VERSION "HNPBNYYYYYYYYYYYYYYYYYYYYYYYYYYYNNNNNNNNNN/4/%%%/4/'%**4NNN///"
NS_ :

BS_:

BU_: BDC546 imc_BUSFX_2_133754 Sender__XXX WC Xsens_Sensor

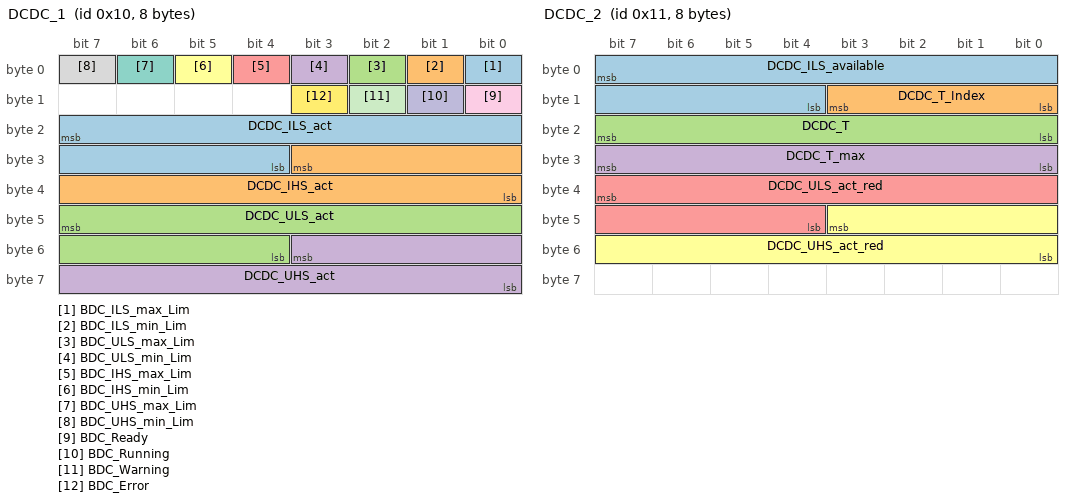
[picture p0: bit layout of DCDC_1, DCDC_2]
BO_ 16 DCDC_1: 8 BDC546
 SG_ BDC_ILS_max_Lim : 0|1@1+ (1,0) [0|1] ""  imc_BUSFX_2_133754
 SG_ BDC_ILS_min_Lim : 1|1@1+ (1,0) [0|1] ""  imc_BUSFX_2_133754
 SG_ BDC_ULS_max_Lim : 2|1@1+ (1,0) [0|1] ""  imc_BUSFX_2_133754
 SG_ BDC_ULS_min_Lim : 3|1@1+ (1,0) [0|1] ""  imc_BUSFX_2_133754
 SG_ BDC_IHS_max_Lim : 4|1@1+ (1,0) [0|1] ""  imc_BUSFX_2_133754
 SG_ BDC_IHS_min_Lim : 5|1@1+ (1,0) [0|1] ""  imc_BUSFX_2_133754
 SG_ BDC_UHS_max_Lim : 6|1@1+ (1,0) [0|1] ""  imc_BUSFX_2_133754
 SG_ BDC_UHS_min_Lim : 7|1@1+ (1,0) [0|1] ""  imc_BUSFX_2_133754
 SG_ BDC_Ready : 8|1@1+ (1,0) [0|1] ""  imc_BUSFX_2_133754
 SG_ BDC_Running : 9|1@1+ (1,0) [0|1] ""  imc_BUSFX_2_133754
 SG_ BDC_Warning : 10|1@1+ (1,0) [0|1] ""  imc_BUSFX_2_133754
 SG_ BDC_Error : 11|1@1+ (1,0) [0|1] ""  imc_BUSFX_2_133754
 SG_ DCDC_ILS_act : 23|12@0+ (2.500000000E-1,-5.120000000E+2) [-5.120000000E+2|5.117500000E+2] "A"  imc_BUSFX_2_133754
 SG_ DCDC_IHS_act : 27|12@0+ (2.500000000E-1,-5.120000000E+2) [-5.120000000E+2|5.117500000E+2] "A"  imc_BUSFX_2_133754
 SG_ DCDC_ULS_act : 47|12@0+ (2.500000000E-1,0.000000000E+0) [0.000000000E+0|1.023750000E+3] "V"  imc_BUSFX_2_133754
 SG_ DCDC_UHS_act : 51|12@0+ (2.500000000E-1,0.000000000E+0) [0.000000000E+0|1.023750000E+3] "V"  imc_BUSFX_2_133754

BO_ 17 DCDC_2: 8 BDC546
 SG_ DCDC_ILS_available : 7|12@0+ (2.500000000E-1,0.000000000E+0) [0.000000000E+0|1.023750000E+3] "A"  imc_BUSFX_2_133754
 SG_ DCDC_T_Index : 11|4@0+ (1.000000000E+0,0.000000000E+0) [0.000000000E+0|1.500000000E+1] ""  imc_BUSFX_2_133754
 SG_ DCDC_T : 23|8@0+ (1.000000000E+0,-4.000000000E+1) [-4.000000000E+1|2.150000000E+2] "C"  imc_BUSFX_2_133754
 SG_ DCDC_T_max : 31|8@0+ (1.000000000E+0,-4.000000000E+1) [-4.000000000E+1|2.150000000E+2] "C"  imc_BUSFX_2_133754
 SG_ DCDC_ULS_act_red : 39|12@0+ (2.500000000E-1,0.000000000E+0) [0.000000000E+0|1.023750000E+3] "V"  imc_BUSFX_2_133754
 SG_ DCDC_UHS_act_red : 43|12@0+ (2.500000000E-1,0.000000000E+0) [0.000000000E+0|1.023750000E+3] "V"  imc_BUSFX_2_133754

BO_ 18 DCDC_3: 8 BDC546
 SG_ BDC_Err_RedNegLS : 0|1@1+ (1,0) [0|1] ""  imc_BUSFX_2_133754
 SG_ BDC_Err_RedPosLS : 1|1@1+ (1,0) [0|1] ""  imc_BUSFX_2_133754
 SG_ BDC_Err_PyroMC : 2|1@1+ (1,0) [0|1] ""  imc_BUSFX_2_133754
 SG_ BDC_Err_TempSens : 8|1@1+ (1,0) [0|1] ""  imc_BUSFX_2_133754
 SG_ BDC_Err_Interlock : 9|1@1+ (1,0) [0|1] ""  imc_BUSFX_2_133754
 SG_ BDC_Err_ISensLS : 10|1@1+ (1,0) [0|1] ""  imc_BUSFX_2_133754
 SG_ BDC_Err_ISensHS : 11|1@1+ (1,0) [0|1] ""  imc_BUSFX_2_133754
 SG_ BDC_Err_BDCMode : 12|1@1+ (1,0) [0|1] ""  imc_BUSFX_2_133754
 SG_ BDC_Err_IHS2ILS : 13|1@1+ (1,0) [0|1] ""  imc_BUSFX_2_133754
 SG_ BDC_Err_RedNegHS : 14|1@1+ (1,0) [0|1] ""  imc_BUSFX_2_133754
 SG_ BDC_Err_RedPosHS : 15|1@1+ (1,0) [0|1] ""  imc_BUSFX_2_133754
 SG_ BDC_Err_Timeout_Recv3 : 19|1@1+ (1,0) [0|1] ""  imc_BUSFX_2_133754
 SG_ BDC_Err_Timeout_Recv2 : 20|1@1+ (1,0) [0|1] ""  imc_BUSFX_2_133754
 SG_ BDC_Err_Timeout_Recv1 : 21|1@1+ (1,0) [0|1] ""  imc_BUSFX_2_133754
 SG_ BDC_Err_CANValue : 22|1@1+ (1,0) [0|1] ""  imc_BUSFX_2_133754
 SG_ BDC_Err_IntSupply : 23|1@1+ (1,0) [0|1] ""  imc_BUSFX_2_133754
 SG_ BDC_Err_FPGA : 3|1@1+ (1,0) [0|1] ""  imc_BUSFX_2_133754
 SG_ BDC_Err_NVSRam : 4|1@1+ (1,0) [0|1] ""  imc_BUSFX_2_133754
 SG_ BDC_Err_Flash : 5|1@1+ (1,0) [0|1] ""  imc_BUSFX_2_133754
 SG_ BDC_Err_EEProm : 6|1@1+ (1,0) [0|1] ""  imc_BUSFX_2_133754
 SG_ BDC_Err_HW_FPGA_Ver : 7|1@1+ (1,0) [0|1] ""  imc_BUSFX_2_133754
 SG_ BDC_Err_CANTx : 16|1@1+ (1,0) [0|1] ""  imc_BUSFX_2_133754
 SG_ BDC_Err_CANRx : 17|1@1+ (1,0) [0|1] ""  imc_BUSFX_2_133754
 SG_ BDC_Err_CANOff : 18|1@1+ (1,0) [0|1] ""  imc_BUSFX_2_133754
 SG_ BDC_Err_OvltSky : 29|1@1+ (1,0) [0|1] ""  imc_BUSFX_2_133754
 SG_ BDC_Err_OvltLS : 30|1@1+ (1,0) [0|1] ""  imc_BUSFX_2_133754
 SG_ BDC_Err_OvltHS : 31|1@1+ (1,0) [0|1] ""  imc_BUSFX_2_133754
 SG_ BDC_War_TempIndD : 32|1@1+ (1,0) [0|1] ""  imc_BUSFX_2_133754
 SG_ BDC_War_TempIndC : 33|1@1+ (1,0) [0|1] ""  imc_BUSFX_2_133754
 SG_ BDC_War_TempIndB : 34|1@1+ (1,0) [0|1] ""  imc_BUSFX_2_133754
 SG_ BDC_War_TempIndA : 35|1@1+ (1,0) [0|1] ""  imc_BUSFX_2_133754
 SG_ BDC_War_Reset : 36|1@1+ (1,0) [0|1] ""  imc_BUSFX_2_133754
 SG_ BDC_War_IMax : 37|1@1+ (1,0) [0|1] ""  imc_BUSFX_2_133754
 SG_ BDC_War_Watchdog : 38|1@1+ (1,0) [0|1] ""  imc_BUSFX_2_133754
 SG_ BDC_War_TempL2x : 45|1@1+ (1,0) [0|1] ""  imc_BUSFX_2_133754
 SG_ BDC_War_TempL1y : 46|1@1+ (1,0) [0|1] ""  imc_BUSFX_2_133754
 SG_ BDC_War_TempL1x : 47|1@1+ (1,0) [0|1] ""  imc_BUSFX_2_133754
 SG_ BDC_Err_FPGA_NVM : 28|1@1+ (1,0) [0|1] ""  imc_BUSFX_2_133754
 SG_ BDC_War_TempL4y : 40|1@1+ (1,0) [0|1] ""  imc_BUSFX_2_133754
 SG_ BDC_War_TempL4x : 41|1@1+ (1,0) [0|1] ""  imc_BUSFX_2_133754
 SG_ BDC_War_TempL3y : 42|1@1+ (1,0) [0|1] ""  imc_BUSFX_2_133754
 SG_ BDC_War_TempL3x : 43|1@1+ (1,0) [0|1] ""  imc_BUSFX_2_133754
 SG_ BDC_War_TempL2y : 44|1@1+ (1,0) [0|1] ""  imc_BUSFX_2_133754
 SG_ BDC_War_HSOvervoltage : 48|1@1+ (1,0) [0|1] ""  imc_BUSFX_2_133754
 SG_ BDC_War_NoIntSupply : 49|1@1+ (1,0) [0|1] ""  imc_BUSFX_2_133754
 SG_ BDC_War_NoHV_UHS : 50|1@1+ (1,0) [0|1] ""  imc_BUSFX_2_133754
 SG_ BDC_War_WrongFPGA : 51|1@1+ (1,0) [0|1] ""  imc_BUSFX_2_133754
 SG_ BDC_War_WrongHW : 52|1@1+ (1,0) [0|1] ""  imc_BUSFX_2_133754
 SG_ BDC_War_PyroVCneg : 53|1@1+ (1,0) [0|1] ""  imc_BUSFX_2_133754
 SG_ BDC_War_PyroVCpos : 54|1@1+ (1,0) [0|1] ""  imc_BUSFX_2_133754
 SG_ BDC_War_Discharge : 55|1@1+ (1,0) [0|1] ""  imc_BUSFX_2_133754
 SG_ BDC_War_CAN_Timeout : 62|1@1+ (1,0) [0|1] ""  imc_BUSFX_2_133754
 SG_ BDC_War_LSOvervoltage : 63|1@1+ (1,0) [0|1] ""  imc_BUSFX_2_133754

BO_ 19 DCDC_4: 8 BDC546
 SG_ BDC_FPGA_SsErr0 : 0|1@1+ (1,0) [0|1] ""  imc_BUSFX_2_133754
 SG_ BDC_FPGA_SsErr1 : 1|1@1+ (1,0) [0|1] ""  imc_BUSFX_2_133754
 SG_ BDC_FPGA_SsErr2 : 2|1@1+ (1,0) [0|1] ""  imc_BUSFX_2_133754
 SG_ BDC_FPGA_SsErr3 : 3|1@1+ (1,0) [0|1] ""  imc_BUSFX_2_133754
 SG_ BDC_FPGA_SsErr4 : 4|1@1+ (1,0) [0|1] ""  imc_BUSFX_2_133754
 SG_ BDC_FPGA_SsErr5 : 5|1@1+ (1,0) [0|1] ""  imc_BUSFX_2_133754
 SG_ BDC_FPGA_SsErr6 : 6|1@1+ (1,0) [0|1] ""  imc_BUSFX_2_133754
 SG_ BDC_FPGA_SsErr7 : 7|1@1+ (1,0) [0|1] ""  imc_BUSFX_2_133754
 SG_ BDC_FPGA_ILmaxErr0 : 8|1@1+ (1,0) [0|1] ""  imc_BUSFX_2_133754
 SG_ BDC_FPGA_ILmaxErr1 : 9|1@1+ (1,0) [0|1] ""  imc_BUSFX_2_133754
 SG_ BDC_FPGA_ILmaxErr2 : 10|1@1+ (1,0) [0|1] ""  imc_BUSFX_2_133754
 SG_ BDC_FPGA_ILmaxErr3 : 11|1@1+ (1,0) [0|1] ""  imc_BUSFX_2_133754
 SG_ BDC_FPGA_ILmaxErr4 : 12|1@1+ (1,0) [0|1] ""  imc_BUSFX_2_133754
 SG_ BDC_FPGA_ILmaxErr5 : 13|1@1+ (1,0) [0|1] ""  imc_BUSFX_2_133754
 SG_ BDC_FPGA_ILmaxErr6 : 14|1@1+ (1,0) [0|1] ""  imc_BUSFX_2_133754
 SG_ BDC_FPGA_ILmaxErr7 : 15|1@1+ (1,0) [0|1] ""  imc_BUSFX_2_133754
 SG_ BDC_FPGA_UBmaxErr : 16|1@1+ (1,0) [0|1] ""  imc_BUSFX_2_133754
 SG_ BDC_FPGA_UA1maxErr : 17|1@1+ (1,0) [0|1] ""  imc_BUSFX_2_133754
 SG_ BDC_FPGA_U15VmaxErr : 18|1@1+ (1,0) [0|1] ""  imc_BUSFX_2_133754
 SG_ BDC_FPGA_IBmaxErr : 23|1@1+ (1,0) [0|1] ""  imc_BUSFX_2_133754
 SG_ BDC_FPGA_GenRglPer : 24|1@1+ (1,0) [0|1] ""  imc_BUSFX_2_133754
 SG_ BDC_FPGA_IllegalAccess : 27|1@1+ (1,0) [0|1] ""  imc_BUSFX_2_133754
 SG_ BDC_FPGA_Hw_Err0 : 28|1@1+ (1,0) [0|1] ""  imc_BUSFX_2_133754
 SG_ BDC_FPGA_Hw_Err1 : 29|1@1+ (1,0) [0|1] ""  imc_BUSFX_2_133754
 SG_ DCDC_FPGA_IntStatUnused3 : 22|4@0- (1.000000000E+0,0.000000000E+0) [-8.000000000E+0|7.000000000E+0] ""  imc_BUSFX_2_133754
 SG_ DCDC_FPGA_IntStatUnused1 : 26|2@0- (1.000000000E+0,0.000000000E+0) [-2.000000000E+0|1.000000000E+0] ""  imc_BUSFX_2_133754
 SG_ DCDC_FPGA_IntStatUnused2 : 31|2@0- (1.000000000E+0,0.000000000E+0) [-2.000000000E+0|1.000000000E+0] ""  imc_BUSFX_2_133754
 SG_ DCDC_CAN_RXCNT : 39|8@0+ (1.000000000E+0,0.000000000E+0) [0.000000000E+0|2.550000000E+2] ""  imc_BUSFX_2_133754
 SG_ DCDC_CAN_TXCNT : 47|8@0+ (1.000000000E+0,0.000000000E+0) [0.000000000E+0|2.550000000E+2] ""  imc_BUSFX_2_133754
 SG_ DCDC_SG_IL_max : 55|16@0+ (3.125000000E-2,-1.024000000E+3) [-1.024000000E+3|1.023968750E+3] "A"  imc_BUSFX_2_133754

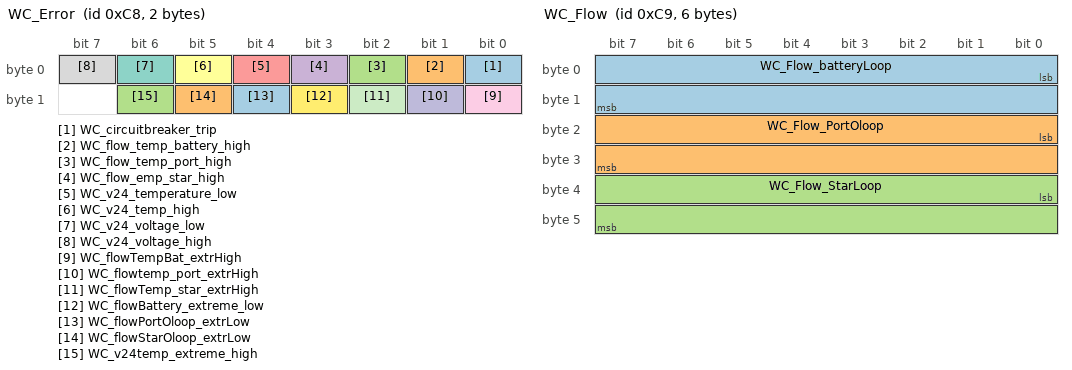
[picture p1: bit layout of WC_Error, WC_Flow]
BO_ 200 WC_Error: 2 Sender__XXX
 SG_ WC_circuitbreaker_trip : 0|1@1+ (1,0) [0|1] ""  imc_BUSFX_2_133754
 SG_ WC_flow_temp_battery_high : 1|1@1+ (1,0) [0|1] ""  imc_BUSFX_2_133754
 SG_ WC_flow_temp_port_high : 2|1@1+ (1,0) [0|1] ""  imc_BUSFX_2_133754
 SG_ WC_flow_emp_star_high : 3|1@1+ (1,0) [0|1] ""  imc_BUSFX_2_133754
 SG_ WC_v24_temperature_low : 4|1@1+ (1,0) [0|1] ""  imc_BUSFX_2_133754
 SG_ WC_v24_temp_high : 5|1@1+ (1,0) [0|1] ""  imc_BUSFX_2_133754
 SG_ WC_v24_voltage_low : 6|1@1+ (1,0) [0|1] ""  imc_BUSFX_2_133754
 SG_ WC_v24_voltage_high : 7|1@1+ (1,0) [0|1] ""  imc_BUSFX_2_133754
 SG_ WC_flowTempBat_extrHigh : 8|1@1+ (1,0) [0|1] ""  imc_BUSFX_2_133754
 SG_ WC_flowtemp_port_extrHigh : 9|1@1+ (1,0) [0|1] ""  imc_BUSFX_2_133754
 SG_ WC_flowTemp_star_extrHigh : 10|1@1+ (1,0) [0|1] ""  imc_BUSFX_2_133754
 SG_ WC_flowBattery_extreme_low : 11|1@1+ (1,0) [0|1] ""  imc_BUSFX_2_133754
 SG_ WC_flowPortOloop_extrLow : 12|1@1+ (1,0) [0|1] ""  imc_BUSFX_2_133754
 SG_ WC_flowStarOloop_extrLow : 13|1@1+ (1,0) [0|1] ""  imc_BUSFX_2_133754
 SG_ WC_v24temp_extreme_high : 14|1@1+ (1,0) [0|1] ""  imc_BUSFX_2_133754

BO_ 201 WC_Flow: 6 Sender__XXX
 SG_ WC_Flow_batteryLoop : 0|16@1+ (7.629510948E-4,0.000000000E+0) [0.000000000E+0|5.000000000E+1] "L/min"  imc_BUSFX_2_133754
 SG_ WC_Flow_PortOloop : 16|16@1+ (7.629510948E-4,0.000000000E+0) [0.000000000E+0|5.000000000E+1] "L/min"  imc_BUSFX_2_133754
 SG_ WC_Flow_StarLoop : 32|16@1+ (7.629510948E-4,0.000000000E+0) [0.000000000E+0|5.000000000E+1] "L/min"  imc_BUSFX_2_133754

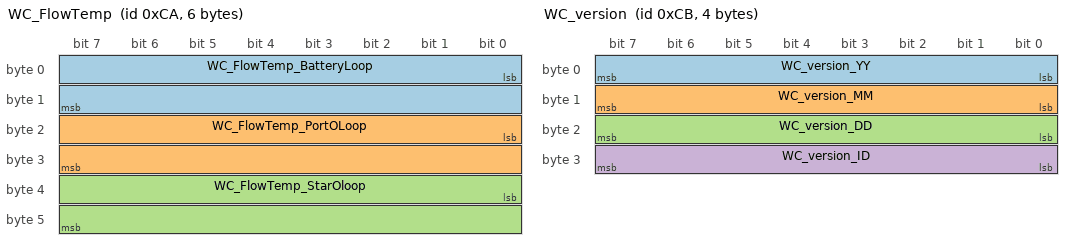
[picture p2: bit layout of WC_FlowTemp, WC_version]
BO_ 202 WC_FlowTemp: 6 Sender__XXX
 SG_ WC_FlowTemp_BatteryLoop : 0|16@1+ (2.288853285E-3,0.000000000E+0) [0.000000000E+0|1.500000000E+2] "C"  imc_BUSFX_2_133754
 SG_ WC_FlowTemp_PortOLoop : 16|16@1+ (2.288853285E-3,0.000000000E+0) [0.000000000E+0|1.500000000E+2] "C"  imc_BUSFX_2_133754
 SG_ WC_FlowTemp_StarOloop : 32|16@1+ (2.288853285E-3,0.000000000E+0) [0.000000000E+0|1.500000000E+2] "C"  imc_BUSFX_2_133754

BO_ 203 WC_version: 4 WC
 SG_ WC_version_YY : 0|8@1- (1.000000000E+0,0.000000000E+0) [-1.280000000E+2|1.270000000E+2] ""  imc_BUSFX_2_133754
 SG_ WC_version_MM : 8|8@1- (1.000000000E+0,0.000000000E+0) [-1.280000000E+2|1.270000000E+2] ""  imc_BUSFX_2_133754
 SG_ WC_version_DD : 16|8@1- (1.000000000E+0,0.000000000E+0) [-1.280000000E+2|1.270000000E+2] ""  imc_BUSFX_2_133754
 SG_ WC_version_ID : 24|8@1- (1.000000000E+0,0.000000000E+0) [-1.280000000E+2|1.270000000E+2] ""  imc_BUSFX_2_133754

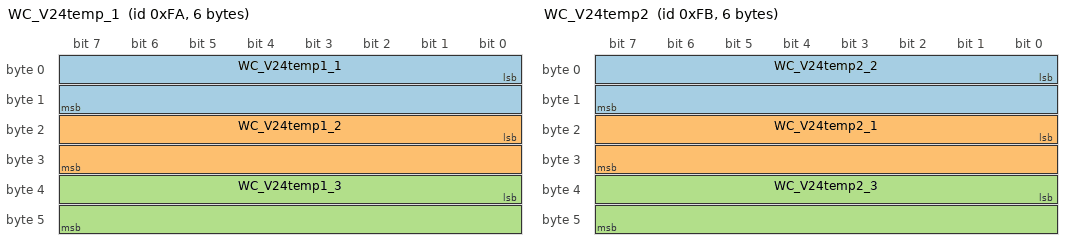
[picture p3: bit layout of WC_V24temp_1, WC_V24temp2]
BO_ 250 WC_V24temp_1: 6 Sender__XXX
 SG_ WC_V24temp1_1 : 0|16@1+ (2.288853280E-3,0.000000000E+0) [0.000000000E+0|1.499999997E+2] "C"  imc_BUSFX_2_133754
 SG_ WC_V24temp1_2 : 16|16@1+ (2.288853280E-3,0.000000000E+0) [0.000000000E+0|1.499999997E+2] "C"  imc_BUSFX_2_133754
 SG_ WC_V24temp1_3 : 32|16@1+ (2.288853280E-3,0.000000000E+0) [0.000000000E+0|1.499999997E+2] "C"  imc_BUSFX_2_133754

BO_ 251 WC_V24temp2: 6 Sender__XXX
 SG_ WC_V24temp2_2 : 0|16@1- (2.288853280E-3,0.000000000E+0) [-7.500114428E+1|7.499885543E+1] "C"  imc_BUSFX_2_133754
 SG_ WC_V24temp2_1 : 16|16@1- (2.288853280E-3,0.000000000E+0) [-7.500114428E+1|7.499885543E+1] "C"  imc_BUSFX_2_133754
 SG_ WC_V24temp2_3 : 32|16@1- (2.288853280E-3,0.000000000E+0) [-7.500114428E+1|7.499885543E+1] "C"  imc_BUSFX_2_133754

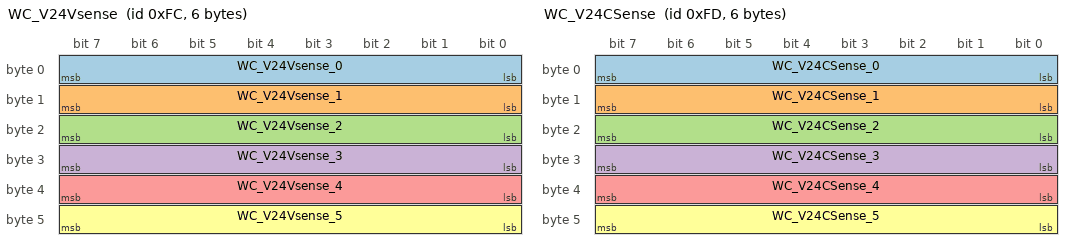
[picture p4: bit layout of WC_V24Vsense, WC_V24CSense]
BO_ 252 WC_V24Vsense: 6 Sender__XXX
 SG_ WC_V24Vsense_0 : 0|8@1+ (1.176470588E-1,0.000000000E+0) [0.000000000E+0|2.999999999E+1] "V"  imc_BUSFX_2_133754
 SG_ WC_V24Vsense_1 : 8|8@1+ (1.176470588E-1,0.000000000E+0) [0.000000000E+0|2.999999999E+1] "V"  imc_BUSFX_2_133754
 SG_ WC_V24Vsense_2 : 16|8@1+ (1.176470588E-1,0.000000000E+0) [0.000000000E+0|2.999999999E+1] "V"  imc_BUSFX_2_133754
 SG_ WC_V24Vsense_3 : 24|8@1+ (1.176470588E-1,0.000000000E+0) [0.000000000E+0|2.999999999E+1] "V"  imc_BUSFX_2_133754
 SG_ WC_V24Vsense_4 : 32|8@1+ (1.176470588E-1,0.000000000E+0) [0.000000000E+0|2.999999999E+1] "V"  imc_BUSFX_2_133754
 SG_ WC_V24Vsense_5 : 40|8@1+ (1.176470588E-1,0.000000000E+0) [0.000000000E+0|2.999999999E+1] "V"  imc_BUSFX_2_133754

BO_ 253 WC_V24CSense: 6 Sender__XXX
 SG_ WC_V24CSense_0 : 0|8@1+ (9.803921568E-2,0.000000000E+0) [0.000000000E+0|2.500000000E+1] "A"  imc_BUSFX_2_133754
 SG_ WC_V24CSense_1 : 8|8@1+ (9.803921568E-2,0.000000000E+0) [0.000000000E+0|2.500000000E+1] "A"  imc_BUSFX_2_133754
 SG_ WC_V24CSense_2 : 16|8@1+ (9.803921568E-2,0.000000000E+0) [0.000000000E+0|2.500000000E+1] "A"  imc_BUSFX_2_133754
 SG_ WC_V24CSense_3 : 24|8@1- (9.803921568E-2,0.000000000E+0) [-1.254901961E+1|1.245098039E+1] "A"  imc_BUSFX_2_133754
 SG_ WC_V24CSense_4 : 32|8@1- (9.803921568E-2,0.000000000E+0) [-1.254901961E+1|1.245098039E+1] "A"  imc_BUSFX_2_133754
 SG_ WC_V24CSense_5 : 40|8@1- (9.803921568E-2,0.000000000E+0) [-1.254901961E+1|1.245098039E+1] "A"  imc_BUSFX_2_133754

BO_ 300 EMS_Error: 8 Sender__XXX
 SG_ EMSFE_cellV_extrLow : 0|1@1+ (1,0) [0|1] ""  imc_BUSFX_2_133754
 SG_ EMSHE_cellV_extrHigh : 1|1@1+ (1,0) [0|1] ""  imc_BUSFX_2_133754
 SG_ EMSFE_WC_nc : 2|1@1+ (1,0) [0|1] ""  imc_BUSFX_2_133754
 SG_ EMSFE_steer_nc : 3|1@1+ (1,0) [0|1] ""  imc_BUSFX_2_133754
 SG_ EMSFE_dashboard_nc : 4|1@1+ (1,0) [0|1] ""  imc_BUSFX_2_133754
 SG_ EMSFE_H2sens_nc : 5|1@1+ (1,0) [0|1] ""  imc_BUSFX_2_133754
 SG_ EMSFE_hydrogenPerc_high : 6|1@1+ (1,0) [0|1] ""  imc_BUSFX_2_133754
 SG_ EMSFE_CBtrip : 7|1@1+ (1,0) [0|1] ""  imc_BUSFX_2_133754
 SG_ EMSFE_BMSslave_nc : 14|1@1+ (1,0) [0|1] ""  imc_BUSFX_2_133754
 SG_ EMSHE_flowPortOloop_extrLow : 16|1@1+ (1,0) [0|1] ""  imc_BUSFX_2_133754
 SG_ EMSHE_flowStarOloop_eLow : 17|1@1+ (1,0) [0|1] ""  imc_BUSFX_2_133754
 SG_ EMSHE_FlowDCDC_extLow : 18|1@1+ (1,0) [0|1] ""  imc_BUSFX_2_133754
 SG_ EMSHE_flowMotor_extLow : 19|1@1+ (1,0) [0|1] ""  imc_BUSFX_2_133754
 SG_ EMSFE_NumbCellsLow : 20|1@1+ (1,0) [0|1] ""  imc_BUSFX_2_133754
 SG_ EMSHE_motorT_extrHigh : 21|1@1+ (1,0) [0|1] ""  imc_BUSFX_2_133754
 SG_ EMSFE_isolation : 22|1@1+ (1,0) [0|1] ""  imc_BUSFX_2_133754
 SG_ EMS_LastFatalError : 60|4@1+ (1.000000000E+0,0.000000000E+0) [0.000000000E+0|1.500000000E+1] ""  imc_BUSFX_2_133754
 SG_ EMSFE_MotorCont_nc : 13|1@1+ (1,0) [0|1] ""  imc_BUSFX_2_133754
 SG_ EMSFE_BMSmaster_nc : 15|1@1+ (1,0) [0|1] ""  imc_BUSFX_2_133754
 SG_ EMS_cellVoltage_high : 39|1@1+ (1,0) [0|1] ""  imc_BUSFX_2_133754
 SG_ EMS_overcurrent : 40|1@1+ (1,0) [0|1] ""  imc_BUSFX_2_133754
 SG_ EMS_motorTemp_high : 41|1@1+ (1,0) [0|1] ""  imc_BUSFX_2_133754
 SG_ EMS_TempBattLoop_high : 42|1@1+ (1,0) [0|1] ""  imc_BUSFX_2_133754
 SG_ EMS_TempPortOloop_high : 43|1@1+ (1,0) [0|1] ""  imc_BUSFX_2_133754
 SG_ EMS_tempStarOloop_high : 44|1@1+ (1,0) [0|1] ""  imc_BUSFX_2_133754
 SG_ EMS_tempDCDCloop_high : 45|1@1+ (1,0) [0|1] ""  imc_BUSFX_2_133754
 SG_ EMSHE_tankpressure_low : 46|1@1+ (1,0) [0|1] ""  imc_BUSFX_2_133754
 SG_ EMS_tempMotorLoop_high : 47|1@1+ (1,0) [0|1] ""  imc_BUSFX_2_133754
 SG_ EMS_FATAL_ERROR : 48|1@1+ (1,0) [0|1] ""  imc_BUSFX_2_133754
 SG_ EMS_TankTemp_high : 49|1@1+ (1,0) [0|1] ""  imc_BUSFX_2_133754
 SG_ skip_deze : 50|1@1+ (1,0) [0|1] ""  imc_BUSFX_2_133754
 SG_ EMSFE_cellT_extrHigh : 23|1@1+ (1,0) [0|1] ""  imc_BUSFX_2_133754
 SG_ EMSHE_TbattLoop_extrHigh : 24|1@1+ (1,0) [0|1] ""  imc_BUSFX_2_133754
 SG_ EMSHE_TportOloop_extrHigh : 25|1@1+ (1,0) [0|1] ""  imc_BUSFX_2_133754
 SG_ EMSHE_TStarOloopExtrHigh : 26|1@1+ (1,0) [0|1] ""  imc_BUSFX_2_133754
 SG_ EMSHE_tDCDCloopExtrHigh : 27|1@1+ (1,0) [0|1] ""  imc_BUSFX_2_133754
 SG_ EMSHE_DCDC_nc : 28|1@1+ (1,0) [0|1] ""  imc_BUSFX_2_133754
 SG_ EMSHE_TmotorLoop_extrHigh : 29|1@1+ (1,0) [0|1] ""  imc_BUSFX_2_133754
 SG_ EMSHE_fFuelcell_nc : 30|1@1+ (1,0) [0|1] ""  imc_BUSFX_2_133754
 SG_ EMSHE_flowBat_extrLow : 31|1@1+ (1,0) [0|1] ""  imc_BUSFX_2_133754
 SG_ EMS_v24_tempLow : 32|1@1+ (1,0) [0|1] ""  imc_BUSFX_2_133754
 SG_ EMS_v24temp_high : 33|1@1+ (1,0) [0|1] ""  imc_BUSFX_2_133754
 SG_ EMS_v24voltage_low : 34|1@1+ (1,0) [0|1] ""  imc_BUSFX_2_133754
 SG_ EMS_v24voltage_high : 35|1@1+ (1,0) [0|1] ""  imc_BUSFX_2_133754
 SG_ EMS_cellTemp_low : 36|1@1+ (1,0) [0|1] ""  imc_BUSFX_2_133754
 SG_ EMS_cellTemp_high : 37|1@1+ (1,0) [0|1] ""  imc_BUSFX_2_133754
 SG_ EMS_cellVoltage_low : 38|1@1+ (1,0) [0|1] ""  imc_BUSFX_2_133754
 SG_ EMS_LastHarbourError : 56|4@1+ (1.000000000E+0,0.000000000E+0) [0.000000000E+0|1.500000000E+1] "0"  imc_BUSFX_2_133754

BO_ 301 EMS_FlowTemp: 4 Sender__XXX
 SG_ EMS_FlowTemp_motorLoop : 7|16@0+ (2.288853285E-3,0.000000000E+0) [0.000000000E+0|1.500000000E+2] "C"  imc_BUSFX_2_133754
 SG_ EMS_FlowTemp_dcdc : 23|16@0+ (2.288853285E-3,0.000000000E+0) [0.000000000E+0|1.500000000E+2] "C"  imc_BUSFX_2_133754

BO_ 302 EMS_flow: 6 Sender__XXX
 SG_ EMS_flow_dcdc : 0|16@1+ (7.629510948E-4,0.000000000E+0) [0.000000000E+0|5.000000000E+1] "L/min"  imc_BUSFX_2_133754
 SG_ EMS_flow_motorLoop : 16|16@1+ (7.629510948E-4,0.000000000E+0) [0.000000000E+0|5.000000000E+1] "L/min"  imc_BUSFX_2_133754

BO_ 303 EMS_OthADC: 8 Sender__XXX
 SG_ EMS_OthADC_TankTemp : 7|16@0- (2.288853280E-3,0.000000000E+0) [-7.500114428E+1|7.499885543E+1] "C"  imc_BUSFX_2_133754
 SG_ EMS_OthADC_TankPress : 23|16@0+ (6.836041810E-3,0.000000000E+0) [0.000000000E+0|4.480000000E+2] "Bar"  imc_BUSFX_2_133754

BO_ 304 EMS_isometer: 2 Sender__XXX
 SG_ EMS_isometer_freq : 0|8@1+ (1.000000000E+0,0.000000000E+0) [0.000000000E+0|2.550000000E+2] "Hz"  imc_BUSFX_2_133754
 SG_ EMS_isometer_DutyCycle : 8|8@1+ (3.921568627E-3,0.000000000E+0) [0.000000000E+0|9.999999999E-1] "%"  imc_BUSFX_2_133754

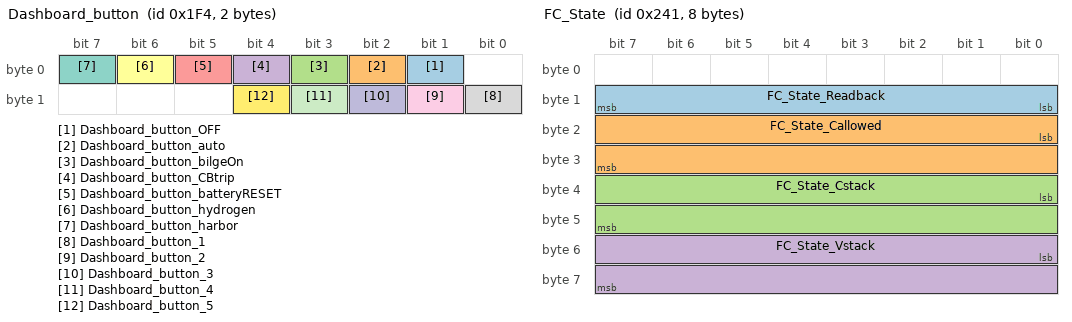
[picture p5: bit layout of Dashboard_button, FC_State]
BO_ 500 Dashboard_button: 2 Sender__XXX
 SG_ Dashboard_button_OFF : 1|1@1+ (1,0) [0|1] ""  imc_BUSFX_2_133754
 SG_ Dashboard_button_auto : 2|1@1+ (1,0) [0|1] ""  imc_BUSFX_2_133754
 SG_ Dashboard_button_bilgeOn : 3|1@1+ (1,0) [0|1] ""  imc_BUSFX_2_133754
 SG_ Dashboard_button_CBtrip : 4|1@1+ (1,0) [0|1] ""  imc_BUSFX_2_133754
 SG_ Dashboard_button_batteryRESET : 5|1@1+ (1,0) [0|1] ""  imc_BUSFX_2_133754
 SG_ Dashboard_button_hydrogen : 6|1@1+ (1,0) [0|1] ""  imc_BUSFX_2_133754
 SG_ Dashboard_button_harbor : 7|1@1+ (1,0) [0|1] ""  imc_BUSFX_2_133754
 SG_ Dashboard_button_1 : 8|1@1+ (1,0) [0|1] ""  imc_BUSFX_2_133754
 SG_ Dashboard_button_2 : 9|1@1+ (1,0) [0|1] ""  imc_BUSFX_2_133754
 SG_ Dashboard_button_3 : 10|1@1+ (1,0) [0|1] ""  imc_BUSFX_2_133754
 SG_ Dashboard_button_4 : 11|1@1+ (1,0) [0|1] ""  imc_BUSFX_2_133754
 SG_ Dashboard_button_5 : 12|1@1+ (1,0) [0|1] ""  imc_BUSFX_2_133754

BO_ 577 FC_State: 8 Sender__XXX
 SG_ FC_State_Readback : 8|8@1- (1.000000000E+0,0.000000000E+0) [-1.280000000E+2|1.270000000E+2] ""  imc_BUSFX_2_133754
 SG_ FC_State_Callowed : 16|16@1+ (1.000000000E-1,0.000000000E+0) [0.000000000E+0|6.553500000E+3] "A"  imc_BUSFX_2_133754
 SG_ FC_State_Cstack : 32|16@1- (1.000000000E-1,0.000000000E+0) [-3.276800000E+3|3.276700000E+3] "A"  imc_BUSFX_2_133754
 SG_ FC_State_Vstack : 48|16@1+ (1.000000000E-1,0.000000000E+0) [0.000000000E+0|6.553500000E+3] "V"  imc_BUSFX_2_133754

BO_ 705 FC_FaultsAlarms: 8 Sender__XXX
 SG_ FC_Faults_UnderV : 0|1@1+ (1,0) [0|1] ""  imc_BUSFX_2_133754
 SG_ FC_Faults_OverTemo : 1|1@1+ (1,0) [0|1] ""  imc_BUSFX_2_133754
 SG_ FC_Faults_HearthBeat : 4|1@1+ (1,0) [0|1] ""  imc_BUSFX_2_133754
 SG_ FC_Faults_Estop : 6|1@1+ (1,0) [0|1] ""  imc_BUSFX_2_133754
 SG_ FC_Faults_LeakCheck : 8|1@1+ (1,0) [0|1] ""  imc_BUSFX_2_133754
 SG_ FC_Faults_FreezeMode : 9|1@1+ (1,0) [0|1] ""  imc_BUSFX_2_133754
 SG_ FC_Faults_CoolFlow : 10|1@1+ (1,0) [0|1] ""  imc_BUSFX_2_133754
 SG_ FC_Faults_Idle : 11|1@1+ (1,0) [0|1] ""  imc_BUSFX_2_133754
 SG_ FC_Faults_AnPurge : 12|1@1+ (1,0) [0|1] ""  imc_BUSFX_2_133754
 SG_ FC_Faults_StkCurrent : 13|1@1+ (1,0) [0|1] ""  imc_BUSFX_2_133754
 SG_ FC_Faults_H2_Opressure : 14|1@1+ (1,0) [0|1] ""  imc_BUSFX_2_133754
 SG_ FC_Faults_H2_Upressure : 15|1@1+ (1,0) [0|1] ""  imc_BUSFX_2_133754
 SG_ FC_Alarms_H2_PSensRange : 32|1@1+ (1,0) [0|1] ""  imc_BUSFX_2_133754
 SG_ FC_Alarms_AirFlowRange : 33|1@1+ (1,0) [0|1] ""  imc_BUSFX_2_133754
 SG_ FC_Alarms_CsenseRange : 34|1@1+ (1,0) [0|1] ""  imc_BUSFX_2_133754
 SG_ FC_Alarms_CoolTempHigh : 35|1@1+ (1,0) [0|1] ""  imc_BUSFX_2_133754
 SG_ FC_Alarms_OverPower : 36|1@1+ (1,0) [0|1] ""  imc_BUSFX_2_133754
 SG_ FC_Alarms_NonRun : 37|1@1+ (1,0) [0|1] ""  imc_BUSFX_2_133754
 SG_ FC_Alarms_BlowFlow : 38|1@1+ (1,0) [0|1] ""  imc_BUSFX_2_133754
 SG_ FC_Alarms_AnPumpSpeed : 39|1@1+ (1,0) [0|1] ""  imc_BUSFX_2_133754
 SG_ FC_Alarms_CoolTemp : 40|1@1+ (1,0) [0|1] ""  imc_BUSFX_2_133754
 SG_ FC_Alarms_BlowVoltLow : 41|1@1+ (1,0) [0|1] ""  imc_BUSFX_2_133754
 SG_ FC_Alarms_Recovery : 42|1@1+ (1,0) [0|1] ""  imc_BUSFX_2_133754
 SG_ FC_Alarms_CoolFlow : 43|1@1+ (1,0) [0|1] ""  imc_BUSFX_2_133754
 SG_ FC_StackLowC : 44|1@1+ (1,0) [0|1] ""  imc_BUSFX_2_133754
 SG_ FC_Alarms_eFCVM_Finger : 45|1@1+ (1,0) [0|1] ""  imc_BUSFX_2_133754
 SG_ FC_Alarms_EEPROM : 46|1@1+ (1,0) [0|1] ""  imc_BUSFX_2_133754
 SG_ FC_Alarms_EMP_Pump : 47|1@1+ (1,0) [0|1] ""  imc_BUSFX_2_133754

BO_ 800 Xsense_SampleTime: 4 Xsens_Sensor
 SG_ Xsense_Timestamp : 7|32@0+ (1.000000000E+0,0.000000000E+0) [0.000000000E+0|4.294967295E+9] "us"  imc_BUSFX_2_133754

BO_ 801 Xsense_StatusWord: 4 Xsens_Sensor
 SG_ Xsense_FilterMode : 1|3@0+ (1.000000000E+0,0.000000000E+0) [0.000000000E+0|7.000000000E+0] ""  imc_BUSFX_2_133754
 SG_ HaveGnssTimePulse : 2|1@1+ (1,0) [0|1] ""  imc_BUSFX_2_133754
 SG_ ClipMagZ : 8|1@1+ (1,0) [0|1] ""  imc_BUSFX_2_133754
 SG_ Retransmitted : 10|1@1+ (1,0) [0|1] ""  imc_BUSFX_2_133754
 SG_ ClippingDetected : 11|1@1+ (1,0) [0|1] ""  imc_BUSFX_2_133754
 SG_ Interpolated : 12|1@1+ (1,0) [0|1] ""  imc_BUSFX_2_133754
 SG_ SyncIn : 13|1@1+ (1,0) [0|1] ""  imc_BUSFX_2_133754
 SG_ SyncOut : 14|1@1+ (1,0) [0|1] ""  imc_BUSFX_2_133754
 SG_ ClipAccX : 16|1@1+ (1,0) [0|1] ""  imc_BUSFX_2_133754
 SG_ ClipAccY : 17|1@1+ (1,0) [0|1] ""  imc_BUSFX_2_133754
 SG_ ClipAccZ : 18|1@1+ (1,0) [0|1] ""  imc_BUSFX_2_133754
 SG_ ClipGyrX : 19|1@1+ (1,0) [0|1] ""  imc_BUSFX_2_133754
 SG_ ClipGyrY : 20|1@1+ (1,0) [0|1] ""  imc_BUSFX_2_133754
 SG_ ClipGyrZ : 21|1@1+ (1,0) [0|1] ""  imc_BUSFX_2_133754
 SG_ ClipMagX : 22|1@1+ (1,0) [0|1] ""  imc_BUSFX_2_133754
 SG_ ClipMagY : 23|1@1+ (1,0) [0|1] ""  imc_BUSFX_2_133754
 SG_ SelfTestOk : 24|1@1+ (1,0) [0|1] ""  imc_BUSFX_2_133754
 SG_ Xsense_RtkStatus : 4|2@0+ (1.000000000E+0,0.000000000E+0) [0.000000000E+0|3.000000000E+0] ""  imc_BUSFX_2_133754
 SG_ OrientationValid : 25|1@1+ (1,0) [0|1] ""  imc_BUSFX_2_133754
 SG_ GpsValid : 26|1@1+ (1,0) [0|1] ""  imc_BUSFX_2_133754
 SG_ RepresentativeMotion : 29|1@1+ (1,0) [0|1] ""  imc_BUSFX_2_133754
 SG_ ExternalClockSynced : 30|1@1+ (1,0) [0|1] ""  imc_BUSFX_2_133754
 SG_ Xsense_NoRotation : 28|2@0+ (1.000000000E+0,0.000000000E+0) [0.000000000E+0|3.000000000E+0] ""  imc_BUSFX_2_133754

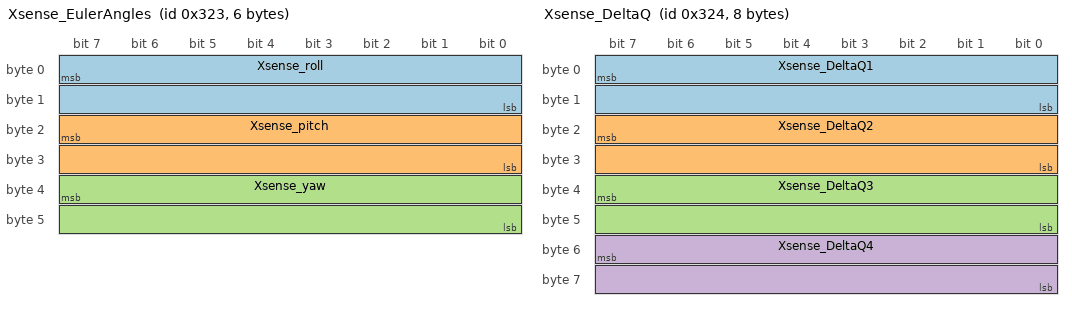
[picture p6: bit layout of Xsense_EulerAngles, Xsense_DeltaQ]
BO_ 803 Xsense_EulerAngles: 6 Xsens_Sensor
 SG_ Xsense_roll : 7|16@0- (7.812500000E-3,0.000000000E+0) [-2.560000000E+2|2.559921875E+2] "deg"  imc_BUSFX_2_133754
 SG_ Xsense_pitch : 23|16@0- (7.812500000E-3,0.000000000E+0) [-2.560000000E+2|2.559921875E+2] "deg"  imc_BUSFX_2_133754
 SG_ Xsense_yaw : 39|16@0- (7.812500000E-3,0.000000000E+0) [-2.560000000E+2|2.559921875E+2] "deg"  imc_BUSFX_2_133754

BO_ 804 Xsense_DeltaQ: 8 Xsens_Sensor
 SG_ Xsense_DeltaQ1 : 7|16@0- (3.051850948E-5,0.000000000E+0) [-1.000030519E+0|1.000000000E+0] "m/s2"  imc_BUSFX_2_133754
 SG_ Xsense_DeltaQ2 : 23|16@0- (3.051850948E-5,0.000000000E+0) [-1.000030519E+0|1.000000000E+0] "m/s2"  imc_BUSFX_2_133754
 SG_ Xsense_DeltaQ3 : 39|16@0- (3.051850948E-5,0.000000000E+0) [-1.000030519E+0|1.000000000E+0] "m/s2"  imc_BUSFX_2_133754
 SG_ Xsense_DeltaQ4 : 55|16@0- (3.051850948E-5,0.000000000E+0) [-1.000030519E+0|1.000000000E+0] "m/s2"  imc_BUSFX_2_133754

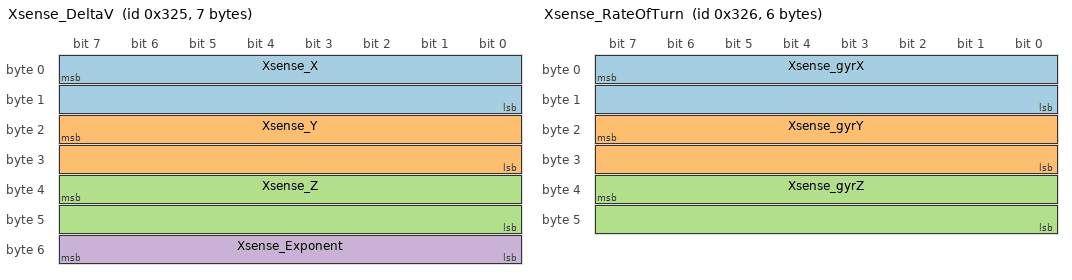
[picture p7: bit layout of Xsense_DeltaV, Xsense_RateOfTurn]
BO_ 805 Xsense_DeltaV: 7 Xsens_Sensor
 SG_ Xsense_X : 7|16@0- (7.629394531E-6,0.000000000E+0) [-2.500000000E-1|2.499923706E-1] "m/s"  imc_BUSFX_2_133754
 SG_ Xsense_Y : 23|16@0- (7.629394531E-6,0.000000000E+0) [-2.500000000E-1|2.499923706E-1] "m/s"  imc_BUSFX_2_133754
 SG_ Xsense_Z : 39|16@0- (7.629394531E-6,0.000000000E+0) [-2.500000000E-1|2.499923706E-1] "m/s"  imc_BUSFX_2_133754
 SG_ Xsense_Exponent : 55|8@0+ (1.000000000E+0,0.000000000E+0) [0.000000000E+0|2.550000000E+2] ""  imc_BUSFX_2_133754

BO_ 806 Xsense_RateOfTurn: 6 Xsens_Sensor
 SG_ Xsense_gyrX : 7|16@0- (1.953125000E-3,0.000000000E+0) [-6.400000000E+1|6.399804688E+1] "rad/s"  imc_BUSFX_2_133754
 SG_ Xsense_gyrY : 23|16@0- (1.953125000E-3,0.000000000E+0) [-6.400000000E+1|6.399804688E+1] "rad/s"  imc_BUSFX_2_133754
 SG_ Xsense_gyrZ : 39|16@0- (1.953125000E-3,0.000000000E+0) [-6.400000000E+1|6.399804688E+1] "rad/s"  imc_BUSFX_2_133754

BO_ 807 Xsense_LongLat: 8 Xsens_Sensor
 SG_ Xsense_latitude : 7|32@0- (5.960464477E-8,0.000000000E+0) [-1.280000000E+2|1.279999999E+2] "deg"  imc_BUSFX_2_133754
 SG_ Xsense_longitude : 39|32@0- (1.192092895E-7,0.000000000E+0) [-2.559999999E+2|2.559999998E+2] "deg"  imc_BUSFX_2_133754

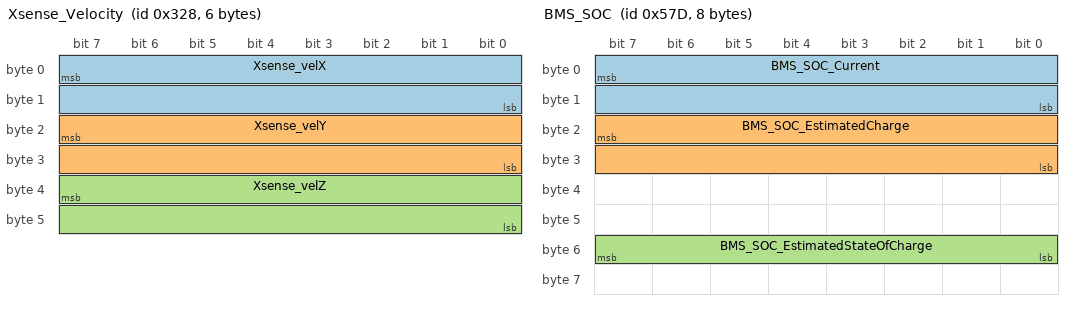
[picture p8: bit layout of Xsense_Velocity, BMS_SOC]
BO_ 808 Xsense_Velocity: 6 Xsens_Sensor
 SG_ Xsense_velX : 7|16@0- (1.562500000E-2,0.000000000E+0) [-5.120000000E+2|5.119843750E+2] "m/s"  imc_BUSFX_2_133754
 SG_ Xsense_velY : 23|16@0- (1.562500000E-2,0.000000000E+0) [-5.120000000E+2|5.119843750E+2] "m/s"  imc_BUSFX_2_133754
 SG_ Xsense_velZ : 39|16@0- (1.562500000E-2,0.000000000E+0) [-5.120000000E+2|5.119843750E+2] "m/s"  imc_BUSFX_2_133754

BO_ 833 FC_Temp: 8 Sender__XXX
 SG_ FC_Temp_Coolant : 0|16@1- (1.000000000E-1,0.000000000E+0) [-3.276800000E+3|3.276700000E+3] "C"  imc_BUSFX_2_133754
 SG_ FC_Temp_CoolantSetPoint : 16|16@1- (1.000000000E-1,0.000000000E+0) [-3.276800000E+3|3.276700000E+3] "C"  imc_BUSFX_2_133754

BO_ 1313 Shunt_Current: 6 Sender__XXX
 SG_ Shunt_Current_msg : 16|32@1+ (1.000000000E+0,0.000000000E+0) [0.000000000E+0|4.294967295E+9] "mA"  imc_BUSFX_2_133754

BO_ 1400 BMS_Overall: 8 Sender__XXX
 SG_ BMS_Overall_NumbOfCellsMSB : 16|8@1+ (2.560000000E+2,0.000000000E+0) [0.000000000E+0|6.528000000E+4] ""  imc_BUSFX_2_133754
 SG_ BMS_Overall_NumbOfCellsLSB : 56|8@1+ (1.000000000E+0,0.000000000E+0) [0.000000000E+0|2.550000000E+2] ""  imc_BUSFX_2_133754

BO_ 1401 BMS_Parameters: 8 Sender__XXX
 SG_ BMS_Voltage_MinCellVoltage : 0|8@1+ (1.000000000E-2,2.000000000E+0) [2.000000000E+0|4.550000000E+0] "V"  imc_BUSFX_2_133754
 SG_ BMS_Voltage_MaxCellVoltage : 8|8@1+ (1.000000000E-2,2.000000000E+0) [2.000000000E+0|4.550000000E+0] "V"  imc_BUSFX_2_133754
 SG_ BMS_Voltage_AvrCellVoltage : 16|8@1+ (1.000000000E-2,2.000000000E+0) [2.000000000E+0|4.550000000E+0] "V"  imc_BUSFX_2_133754
 SG_ BMS_Voltage_TotalVbyte2 : 24|8@1+ (2.560000000E+0,0.000000000E+0) [0.000000000E+0|6.528000000E+2] "V"  imc_BUSFX_2_133754
 SG_ BMS_Voltage_TotalVbyte3 : 32|8@1+ (1.000000000E-2,0.000000000E+0) [0.000000000E+0|2.550000000E+0] "V"  imc_BUSFX_2_133754
 SG_ BMS_Voltage_TotalVbyte0 : 40|8@1+ (1.677721600E+5,0.000000000E+0) [0.000000000E+0|4.278190080E+7] "V"  imc_BUSFX_2_133754
 SG_ BMS_Voltage_TotalVbyte1 : 40|8@1+ (6.553600000E+2,0.000000000E+0) [0.000000000E+0|1.671168000E+5] "V"  imc_BUSFX_2_133754

BO_ 1403 BMS_CellBallancing: 8 Sender__XXX
 SG_ BMS_CellBallancing_Avg : 0|8@1+ (3.921568627E-1,0.000000000E+0) [0.000000000E+0|9.999999999E+1] "%"  imc_BUSFX_2_133754
 SG_ BMS_CellBallancing_Min : 0|8@1+ (3.921568627E-1,0.000000000E+0) [0.000000000E+0|9.999999999E+1] "%"  imc_BUSFX_2_133754
 SG_ BMS_CellBallancing_Max : 8|8@1+ (3.921568627E-1,0.000000000E+0) [0.000000000E+0|9.999999999E+1] "%"  imc_BUSFX_2_133754

BO_ 1405 BMS_SOC: 8 Sender__XXX
 SG_ BMS_SOC_Current : 7|16@0- (1.000000000E-1,0.000000000E+0) [-3.276800000E+3|3.276700000E+3] "A"  imc_BUSFX_2_133754
 SG_ BMS_SOC_EstimatedCharge : 23|16@0- (1.000000000E-1,0.000000000E+0) [-3.276800000E+3|3.276700000E+3] "Ah"  imc_BUSFX_2_133754
 SG_ BMS_SOC_EstimatedStateOfCharge : 48|8@1- (1.000000000E+0,0.000000000E+0) [-1.280000000E+2|1.270000000E+2] "%"  imc_BUSFX_2_133754

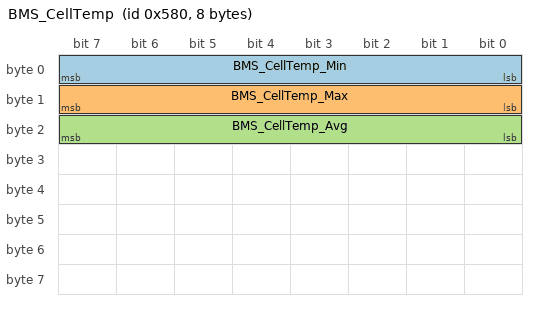
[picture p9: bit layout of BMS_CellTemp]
BO_ 1408 BMS_CellTemp: 8 Sender__XXX
 SG_ BMS_CellTemp_Min : 0|8@1+ (1.000000000E+0,-1.000000000E+2) [-1.000000000E+2|1.550000000E+2] "C"  imc_BUSFX_2_133754
 SG_ BMS_CellTemp_Max : 8|8@1+ (1.000000000E+0,-1.000000000E+2) [-1.000000000E+2|1.550000000E+2] "C"  imc_BUSFX_2_133754
 SG_ BMS_CellTemp_Avg : 16|8@1+ (1.000000000E+0,-1.000000000E+2) [-1.000000000E+2|1.550000000E+2] "C"  imc_BUSFX_2_133754

BO_ 1600 HydrogenSensor: 8 Sender__XXX
 SG_ HydrogenSensor_HydrogenLevel : 0|8@1- (2.000000000E-2,-4.000000000E-1) [-2.960000000E+0|2.140000000E+0] "%"  imc_BUSFX_2_133754

BO_ 701 MC_speed: 3 Sender__XXX
 SG_ MC_speed : 8|16@1- (1.220740379E-1,0.000000000E+0) [-4.000122074E+3|4.000000000E+3] ""  imc_BUSFX_2_133754

BO_ 305 EMS_Status_Message: 8 Sender__XXX
 SG_ EMS_Config_Tank : 1|1@1+ (1,0) [0|1] ""  imc_BUSFX_2_133754
 SG_ motorisstarted : 15|1@1+ (1,0) [0|1] ""  imc_BUSFX_2_133754

BO_ 306 EMS_send_rpm: 3 Sender__XXX
 SG_ EMS_send_rpm : 8|16@1- (1.220740379E-1,0.000000000E+0) [-4.000122074E+3|4.000000000E+3] ""  imc_BUSFX_2_133754
 SG_ EMS_send_drivereverse : 0|8@1+ (1.000000000E+0,0.000000000E+0) [0.000000000E+0|2.550000000E+2] ""  imc_BUSFX_2_133754

BO_ 700 MC_temperature: 8 Sender__XXX
 SG_ MC_temperature : 8|16@1- (1.000000000E+0,0.000000000E+0) [-3.276800000E+4|3.276700000E+4] "C"  imc_BUSFX_2_133754

BO_ 702 MC_Power: 8 Sender__XXX
 SG_ MC_Power : 8|16@1- (1.000000000E+0,0.000000000E+0) [-3.276800000E+4|3.276700000E+4] "W"  imc_BUSFX_2_133754

CM_ "CAN-database created with: imc DEVICES 2.13 Rev. 11";
CM_ BO_ 16 "Msg 1 from BDC546 to SG (main message) 10ms";
CM_ SG_ 16 BDC_ILS_max_Lim "Max low side current limiter active. Values: 1 On 0 Off ";
CM_ SG_ 16 BDC_ILS_min_Lim "Min low side current limiter active. Values: 1 On 0 Off ";
CM_ SG_ 16 BDC_ULS_max_Lim "Max low side voltage limiter active. Values: 1 On 0 Off ";
CM_ SG_ 16 BDC_ULS_min_Lim "Min low side voltage limiter active. Values: 1 On 0 Off ";
CM_ SG_ 16 BDC_IHS_max_Lim "Max high side current limiter active. Values: 1 On 0 Off ";
CM_ SG_ 16 BDC_IHS_min_Lim "Min high side current limiter active. Values: 1 On 0 Off ";
CM_ SG_ 16 BDC_UHS_max_Lim "Max high side voltage limiter active. Values: 1 On 0 Off ";
CM_ SG_ 16 BDC_UHS_min_Lim "Min high side voltage limiter active. Values: 1 On 0 Off ";
CM_ SG_ 16 BDC_Ready "BDC546 Ready. Values: 1 On 0 Off ";
CM_ SG_ 16 BDC_Running "BDC546 Running. Values: 1 On 0 Off ";
CM_ SG_ 16 BDC_Warning "BDC546 Warning. Values: 1 On 0 Off ";
CM_ SG_ 16 BDC_Error "BDC546 Error. Values: 1 On 0 Off ";
CM_ SG_ 16 DCDC_ILS_act "Low side current value";
CM_ SG_ 16 DCDC_IHS_act "High side current value";
CM_ SG_ 16 DCDC_ULS_act "Low side voltage value";
CM_ SG_ 16 DCDC_UHS_act "High side voltage value";
CM_ BO_ 17 "Msg 2 from BDC546 to SG (Values and Config) 200ms";
CM_ SG_ 17 DCDC_ILS_available "Max low side current due to derating";
CM_ SG_ 17 DCDC_T_Index "Measured temperature count (index)";
CM_ SG_ 17 DCDC_T "Measured temperature at this index";
CM_ SG_ 17 DCDC_T_max "Max measured temperatur BDC546";
CM_ SG_ 17 DCDC_ULS_act_red "Redundant low side voltage value";
CM_ SG_ 17 DCDC_UHS_act_red "Redundant high side voltage value";
CM_ BO_ 18 "Msg 3 from BDC546 to SG (Errors and Warnings) 200ms";
CM_ SG_ 18 BDC_Err_RedNegLS "BDC Error negative difference redundant voltage measurement low-side";
CM_ SG_ 18 BDC_Err_RedPosLS "BDC Error positive difference redundant voltage measurement low-side";
CM_ SG_ 18 BDC_Err_PyroMC "BDC Error Pyrofuse ignition";
CM_ SG_ 18 BDC_Err_TempSens "BDC Error Temperatur sensors (at least two sensors defective)";
CM_ SG_ 18 BDC_Err_Interlock "BDC Error Interlock detection";
CM_ SG_ 18 BDC_Err_ISensLS "BDC Error current sensor low-side at initialisation";
CM_ SG_ 18 BDC_Err_ISensHS "BDC Error current sensor high-side at initialisation";
CM_ SG_ 18 BDC_Err_BDCMode "BDC Error Not the same mode between CAN and PARAM values";
CM_ SG_ 18 BDC_Err_IHS2ILS "BDC Error plausibility IHS to ILS";
CM_ SG_ 18 BDC_Err_RedNegHS "BDC Error negative difference redundant voltage measurement high-side";
CM_ SG_ 18 BDC_Err_RedPosHS "BDC Error postive difference redundant voltage measurement high-side";
CM_ SG_ 18 BDC_Err_Timeout_Recv3 "BDC Error message Recv3 timeout";
CM_ SG_ 18 BDC_Err_Timeout_Recv2 "BDC Error message Recv2 timeout";
CM_ SG_ 18 BDC_Err_Timeout_Recv1 "BDC Error message Recv1 timeout";
CM_ SG_ 18 BDC_Err_CANValue "BDC Error received CAN signal with wrong value";
CM_ SG_ 18 BDC_Err_IntSupply "BDC Error Internal supply (15V) not running if HV is connected";
CM_ SG_ 18 BDC_Err_FPGA "BDC Error from FPGA";
CM_ SG_ 18 BDC_Err_NVSRam "BDC Error NVSRam not available or wrong version";
CM_ SG_ 18 BDC_Err_Flash "BDC Error flash CRC wrong";
CM_ SG_ 18 BDC_Err_EEProm "BDC Error main parameter set failure";
CM_ SG_ 18 BDC_Err_HW_FPGA_Ver "BDC Error HW or FPGA version not korrekt";
CM_ SG_ 18 BDC_Err_CANTx "BDC Error too many CAN Tx failures";
CM_ SG_ 18 BDC_Err_CANRx "BDC Error too many CAN Rx failures";
CM_ SG_ 18 BDC_Err_CANOff "BDC Error CAN off at uC";
CM_ SG_ 18 BDC_Err_OvltSky "BDC Error internal supply (15V) overvoltage";
CM_ SG_ 18 BDC_Err_OvltLS "BDC Error low-side overvoltage";
CM_ SG_ 18 BDC_Err_OvltHS "BDC Error high-side overvoltage";
CM_ SG_ 18 BDC_War_TempIndD "BDC Warning temperatur sensor inductor D defective";
CM_ SG_ 18 BDC_War_TempIndC "BDC Warning temperatur sensor inductor C defective";
CM_ SG_ 18 BDC_War_TempIndB "BDC Warning temperatur sensor inductor B defective";
CM_ SG_ 18 BDC_War_TempIndA "BDC Warning temperatur sensor inductor A defective";
CM_ SG_ 18 BDC_War_Reset "BDC Warning System was reset";
CM_ SG_ 18 BDC_War_IMax "BDC Warning Derating active";
CM_ SG_ 18 BDC_War_Watchdog "BDC Warning Watchdog had caused the last reset";
CM_ SG_ 18 BDC_War_TempL2x "BDC Warning temperatur sensor module L2x defective";
CM_ SG_ 18 BDC_War_TempL1y "BDC Warning temperatur sensor module L1y defective";
CM_ SG_ 18 BDC_War_TempL1x "BDC Warning temperatur sensor module L1x defective";
CM_ SG_ 18 BDC_Err_FPGA_NVM "BDC Error FPGA NVM CRC check";
CM_ SG_ 18 BDC_War_TempL4y "BDC Warning temperatur sensor module L4y defective";
CM_ SG_ 18 BDC_War_TempL4x "BDC Warning temperatur sensor module L4x defective";
CM_ SG_ 18 BDC_War_TempL3y "BDC Warning temperatur sensor module L3y defective";
CM_ SG_ 18 BDC_War_TempL3x "BDC Warning temperatur sensor module L3x defective";
CM_ SG_ 18 BDC_War_TempL2y "BDC Warning temperatur sensor module L2y defective";
CM_ SG_ 18 BDC_War_HSOvervoltage "BDC Warning FPGA has switched off with HS Overvoltage";
CM_ SG_ 18 BDC_War_NoIntSupply "BDC Warning no internal supply (15V)";
CM_ SG_ 18 BDC_War_NoHV_UHS "BDC Warning no HV at high-side";
CM_ SG_ 18 BDC_War_WrongFPGA "BDC Warning wrong FPGA version";
CM_ SG_ 18 BDC_War_WrongHW "BDC Warning wrong HW versions";
CM_ SG_ 18 BDC_War_PyroVCneg "BDC Warning Pyrofuse negative resistance wrong";
CM_ SG_ 18 BDC_War_PyroVCpos "BDC Warning Pyrofuse positive resistance wrong";
CM_ SG_ 18 BDC_War_Discharge "BDC Warning Voltage too high after discharge";
CM_ SG_ 18 BDC_War_CAN_Timeout "BDC Warning CAN Timeout was detected";
CM_ SG_ 18 BDC_War_LSOvervoltage "BDC Warning FPGA has switched off with LS Overvoltage";
CM_ BO_ 19 "Msg 3 from BDC546 to SG (Errors and Warnings) 200ms";
CM_ SG_ 19 DCDC_SG_IL_max "Minimum inductor current measured";
CM_ SG_ 577 FC_State_Callowed "Current Draw Allowed";
CM_ SG_ 577 FC_State_Cstack "Fuel Cell Current";
CM_ SG_ 577 FC_State_Vstack "Fuel Cell";
CM_ SG_ 705 FC_Faults_UnderV "Stack Under Voltage Fault";
CM_ SG_ 705 FC_Faults_OverTemo "Coolant Over-Temperature Fault";
CM_ SG_ 705 FC_Faults_HearthBeat "Command Heart Beat Fault";
CM_ SG_ 705 FC_Faults_Estop "Internal System Estop Fault";
CM_ SG_ 705 FC_Faults_LeakCheck "Leak Check Failed Fault";
CM_ SG_ 705 FC_Faults_FreezeMode "Freeze Mode Fault";
CM_ SG_ 705 FC_Faults_CoolFlow "Coolant Low Flow Fault";
CM_ SG_ 705 FC_Faults_Idle "Idle Fault";
CM_ SG_ 705 FC_Faults_AnPurge "Anode Purge Fault";
CM_ SG_ 705 FC_Faults_StkCurrent "Stack Current Fault";
CM_ SG_ 705 FC_Faults_H2_Opressure "H2 Supply Over Pressure Fault";
CM_ SG_ 705 FC_Faults_H2_Upressure "H2 Supply Under Pressure Fault";
CM_ SG_ 705 FC_Alarms_H2_PSensRange "H2 Pressure Sensor Out of Range Alarm";
CM_ SG_ 705 FC_Alarms_AirFlowRange "Air Flow Out of Range Alarm";
CM_ SG_ 705 FC_Alarms_CsenseRange "Current Sensor Out of Range Alarm";
CM_ SG_ 705 FC_Alarms_CoolTempHigh "Coolant Temperature High Alarm";
CM_ SG_ 705 FC_Alarms_OverPower "System Over-Power Alarm";
CM_ SG_ 705 FC_Alarms_NonRun "Air Flow in a Non-Run State Alarm";
CM_ SG_ 705 FC_Alarms_BlowFlow "Blower Low Flow Alarm";
CM_ SG_ 705 FC_Alarms_AnPumpSpeed "Anode Pump Over/Under Speed Alarm";
CM_ SG_ 705 FC_Alarms_CoolTemp "Coolant Temp. Out of Range Alarm";
CM_ SG_ 705 FC_Alarms_BlowVoltLow "Blower Low Voltage Alarm";
CM_ SG_ 705 FC_Alarms_Recovery "Recovery Alarm";
CM_ SG_ 705 FC_Alarms_CoolFlow "Coolant Low Flow Alarm";
CM_ SG_ 705 FC_StackLowC "Stack Low Current Alarm";
CM_ SG_ 705 FC_Alarms_eFCVM_Finger "eFCVM Bad Finger Alarm";
CM_ SG_ 705 FC_Alarms_EEPROM "EEPROM Error Alarm";
CM_ SG_ 705 FC_Alarms_EMP_Pump "EMP Pump Alarm";
CM_ SG_ 801 Xsense_FilterMode "Mask for the 3 bit filter mode field. Values: 0 false 1 true ";
CM_ SG_ 801 HaveGnssTimePulse "Indicates that the 1PPS GNSS time pulse is present. Values: 0 false 1 true ";
CM_ SG_ 801 ClipMagZ "Indicates if there was clipping on the Z-axis of the magnetometer. Values: 0 false 1 true ";
CM_ SG_ 801 Retransmitted "When set Indicates the sample was received as a retransmission. Values: 0 false 1 true ";
CM_ SG_ 801 ClippingDetected "When set Indicates clipping has occurred. Values: 0 false 1 true ";
CM_ SG_ 801 Interpolated "When set Indicates the sample is an interpolation between other samples. Values: 0 false 1 true ";
CM_ SG_ 801 SyncIn "When set indicates a sync-in event has been triggered. Values: 0 false 1 true ";
CM_ SG_ 801 SyncOut "When set Indicates a sync-out event has been generated. Values: 0 false 1 true ";
CM_ SG_ 801 ClipAccX "Indicates if there was clipping on the X-axis of the accelerometer. Values: 0 false 1 true ";
CM_ SG_ 801 ClipAccY "Indicates if there was clipping on the Y-axis of the accelerometer. Values: 0 false 1 true ";
CM_ SG_ 801 ClipAccZ "Indicates if there was clipping on the Z-axis of the accelerometer. Values: 0 false 1 true ";
CM_ SG_ 801 ClipGyrX "Indicates if there was clipping on the X-axis of the gyroscope. Values: 0 false 1 true ";
CM_ SG_ 801 ClipGyrY "Indicates if there was clipping on the Y-axis of the gyroscope. Values: 0 false 1 true ";
CM_ SG_ 801 ClipGyrZ "Indicates if there was clipping on the Z-axis of the gyroscope. Values: 0 false 1 true ";
CM_ SG_ 801 ClipMagX "Indicates if there was clipping on the X-axis of the magnetometer. Values: 0 false 1 true ";
CM_ SG_ 801 ClipMagY "Indicates if there was clipping on the Y-axis of the magnetometer. Values: 0 false 1 true ";
CM_ SG_ 801 SelfTestOk "Set when the self test result was ok. Values: 0 false 1 true ";
CM_ SG_ 801 Xsense_RtkStatus "Mask for 2 bit RTK status field. Values: 0 No RTK 1 RTK floating 2 RTK fixed ";
CM_ SG_ 801 OrientationValid "Set when the computed orientation is valid. The orientation may be invalid during startup or when the Xsens_Sensor data is clipping during violent (for the device) motion. Values: 0 false 1 true ";
CM_ SG_ 801 GpsValid "Set when the device has a GPS receiver and the receiver says that there is a GPS position fix.. Values: 0 false 1 true ";
CM_ SG_ 801 RepresentativeMotion "Indicates if the In-Run Compass Calibration is doing the representative motion analysis. Values: 0 false 1 true ";
CM_ SG_ 801 ExternalClockSynced "Indicates whether the internal clock is synced with an external clock (Either GNNS or custom provided clock sync). Values: 0 false 1 true ";
CM_ SG_ 801 Xsense_NoRotation "Values: 1 Aborted 2 SamplesRejected 3 RunningNormally ";
CM_ BO_ 833 "Coolant Temperature Transmission from the PDC";
CM_ SG_ 1400 BMS_Overall_NumbOfCellsMSB "Add MSB and LSB to get total";
CM_ SG_ 1400 BMS_Overall_NumbOfCellsLSB "Add MSB and LSB to get total";
CM_ SG_ 1401 BMS_Voltage_TotalVbyte2 "Add all bytes to get total";
CM_ SG_ 1401 BMS_Voltage_TotalVbyte3 "Add all bytes to get total";
CM_ SG_ 1401 BMS_Voltage_TotalVbyte0 "Add all bytes to get total";
CM_ SG_ 1401 BMS_Voltage_TotalVbyte1 "Add all bytes to get total";
CM_ BU_ imc_BUSFX_2_133754 "Serial number: 133754
Slot number: 1
Node number: 1";

BA_DEF_ BO_ "GenMsgCycleTimeus" INT 100 60000000;
BA_DEF_ SG_ "SystemSignalLongSymbol" STRING ;

BA_DEF_DEF_  "GenMsgCycleTimeus" 100000;
BA_DEF_DEF_  "SystemSignalLongSymbol" "";

BA_ "GenMsgCycleTimeus" BO_ 16 10000;
BA_ "GenMsgCycleTimeus" BO_ 17 200000;
BA_ "GenMsgCycleTimeus" BO_ 18 200000;
BA_ "GenMsgCycleTimeus" BO_ 19 200000;
BA_ "GenMsgCycleTimeus" BO_ 577 200000;
BA_ "GenMsgCycleTimeus" BO_ 833 200000;
BA_ "GenMsgCycleTimeus" BO_ 1313 10000;
BA_ "SystemSignalLongSymbol" SG_ 705 tes_if_there_was_clipping_on_the "tes_if_there_was_clipping_on_the_Z_axis_of_the_magnetometer__Values__0_false_1_true_";
BA_ "SystemSignalLongSymbol" SG_ 705 tes_if_there_was_clipping_000016 "tes_if_there_was_clipping_on_the_Z_axis_of_the_magnetometer__Values__0_false_1_true_";
BA_ "SystemSignalLongSymbol" SG_ 705 tes_if_there_was_clipping_000017 "tes_if_there_was_clipping_on_the_Z_axis_of_the_magnetometer__Values__0_false_1_true_";
BA_ "SystemSignalLongSymbol" SG_ 705 tes_if_there_was_clipping_000018 "tes_if_there_was_clipping_on_the_Z_axis_of_the_magnetometer__Values__0_false_1_true_";
BA_ "SystemSignalLongSymbol" SG_ 705 tes_if_there_was_clipping_000019 "tes_if_there_was_clipping_on_the_Z_axis_of_the_magnetometer__Values__0_false_1_true_";
BA_ "SystemSignalLongSymbol" SG_ 705 tes_if_there_was_clipping_000020 "tes_if_there_was_clipping_on_the_Z_axis_of_the_magnetometer__Values__0_false_1_true_";
BA_ "SystemSignalLongSymbol" SG_ 705 tes_if_there_was_clipping_000021 "tes_if_there_was_clipping_on_the_Z_axis_of_the_magnetometer__Values__0_false_1_true_";
BA_ "SystemSignalLongSymbol" SG_ 705 tes_if_there_was_clipping_000022 "tes_if_there_was_clipping_on_the_Z_axis_of_the_magnetometer__Values__0_false_1_true_";
BA_ "SystemSignalLongSymbol" SG_ 705 tes_if_there_was_clipping_000023 "tes_if_there_was_clipping_on_the_Z_axis_of_the_magnetometer__Values__0_false_1_true_";
BA_ "SystemSignalLongSymbol" SG_ 705 tes_if_there_was_clipping_000024 "tes_if_there_was_clipping_on_the_Z_axis_of_the_magnetometer__Values__0_false_1_true_";
BA_ "SystemSignalLongSymbol" SG_ 705 tes_if_there_was_clipping_000025 "tes_if_there_was_clipping_on_the_Z_axis_of_the_magnetometer__Values__0_false_1_true_";
BA_ "SystemSignalLongSymbol" SG_ 705 tes_if_there_was_clipping_000026 "tes_if_there_was_clipping_on_the_Z_axis_of_the_magnetometer__Values__0_false_1_true_";
BA_ "SystemSignalLongSymbol" SG_ 705 tes_if_there_was_clipping_000027 "tes_if_there_was_clipping_on_the_Z_axis_of_the_magnetometer__Values__0_false_1_true_";
BA_ "SystemSignalLongSymbol" SG_ 705 tes_if_there_was_clipping_000028 "tes_if_there_was_clipping_on_the_Z_axis_of_the_magnetometer__Values__0_false_1_true_";
BA_ "SystemSignalLongSymbol" SG_ 705 tes_if_there_was_clipping_000029 "tes_if_there_was_clipping_on_the_Z_axis_of_the_magnetometer__Values__0_false_1_true_";
BA_ "SystemSignalLongSymbol" SG_ 705 tes_if_there_was_clipping_000030 "tes_if_there_was_clipping_on_the_Z_axis_of_the_magnetometer__Values__0_false_1_true_";
BA_ "SystemSignalLongSymbol" SG_ 801 tes_whether_the_internal_clock_i "tes_whether_the_internal_clock_is_synced_with_an_external_clock__Either_GNNS_or_custom_provided_clock_sync___Values__0_false_1_t";
BA_ "SystemSignalLongSymbol" SG_ 801 tes_whether_the_internal__000031 "tes_whether_the_internal_clock_is_synced_with_an_external_clock__Either_GNNS_or_custom_provided_clock_sync___Values__0_false_1_t";
BA_ "SystemSignalLongSymbol" SG_ 801 tes_whether_the_internal__000032 "tes_whether_the_internal_clock_is_synced_with_an_external_clock__Either_GNNS_or_custom_provided_clock_sync___Values__0_false_1_t";
BA_ "SystemSignalLongSymbol" SG_ 801 tes_whether_the_internal__000033 "tes_whether_the_internal_clock_is_synced_with_an_external_clock__Either_GNNS_or_custom_provided_clock_sync___Values__0_false_1_t";
BA_ "SystemSignalLongSymbol" SG_ 801 tes_whether_the_internal__000034 "tes_whether_the_internal_clock_is_synced_with_an_external_clock__Either_GNNS_or_custom_provided_clock_sync___Values__0_false_1_t";
BA_ "SystemSignalLongSymbol" SG_ 801 tes_whether_the_internal__000035 "tes_whether_the_internal_clock_is_synced_with_an_external_clock__Either_GNNS_or_custom_provided_clock_sync___Values__0_false_1_t";
BA_ "SystemSignalLongSymbol" SG_ 801 tes_whether_the_internal__000036 "tes_whether_the_internal_clock_is_synced_with_an_external_clock__Either_GNNS_or_custom_provided_clock_sync___Values__0_false_1_t";
BA_ "SystemSignalLongSymbol" SG_ 801 tes_whether_the_internal__000037 "tes_whether_the_internal_clock_is_synced_with_an_external_clock__Either_GNNS_or_custom_provided_clock_sync___Values__0_false_1_t";
BA_ "SystemSignalLongSymbol" SG_ 801 tes_whether_the_internal__000038 "tes_whether_the_internal_clock_is_synced_with_an_external_clock__Either_GNNS_or_custom_provided_clock_sync___Values__0_false_1_t";
BA_ "SystemSignalLongSymbol" SG_ 801 tes_whether_the_internal__000039 "tes_whether_the_internal_clock_is_synced_with_an_external_clock__Either_GNNS_or_custom_provided_clock_sync___Values__0_false_1_t";
BA_ "SystemSignalLongSymbol" SG_ 801 tes_whether_the_internal__000040 "tes_whether_the_internal_clock_is_synced_with_an_external_clock__Either_GNNS_or_custom_provided_clock_sync___Values__0_false_1_t";
BA_ "SystemSignalLongSymbol" SG_ 801 tes_whether_the_internal__000041 "tes_whether_the_internal_clock_is_synced_with_an_external_clock__Either_GNNS_or_custom_provided_clock_sync___Values__0_false_1_t";
BA_ "SystemSignalLongSymbol" SG_ 801 tes_whether_the_internal__000042 "tes_whether_the_internal_clock_is_synced_with_an_external_clock__Either_GNNS_or_custom_provided_clock_sync___Values__0_false_1_t";
BA_ "SystemSignalLongSymbol" SG_ 801 tes_whether_the_internal__000043 "tes_whether_the_internal_clock_is_synced_with_an_external_clock__Either_GNNS_or_custom_provided_clock_sync___Values__0_false_1_t";
BA_ "SystemSignalLongSymbol" SG_ 801 tes_whether_the_internal__000044 "tes_whether_the_internal_clock_is_synced_with_an_external_clock__Either_GNNS_or_custom_provided_clock_sync___Values__0_false_1_t";
BA_ "SystemSignalLongSymbol" SG_ 801 tes_whether_the_internal__000045 "tes_whether_the_internal_clock_is_synced_with_an_external_clock__Either_GNNS_or_custom_provided_clock_sync___Values__0_false_1_t";
